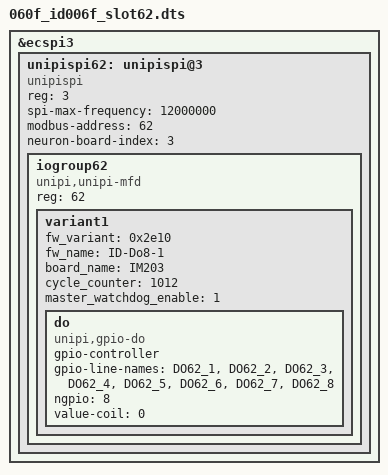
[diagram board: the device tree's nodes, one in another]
/dts-v1/;


/plugin/;

/ {
	fragment@1 {
		
		target = <&ecspi3>;
		__overlay__ {
			status = "okay";
			#address-cells = <1>;
			#size-cells = <0>;

			unipispi62: unipispi@3 {
				compatible = "unipispi";
				reg = <3>;
				status = "okay";
				spi-max-frequency = <12000000>;
				modbus-address = <62>;
				neuron-board-index = <3>;
			};
		};

	};

	fragment@2 {
		target = <&unipispi62>;
		__overlay__ {
			#address-cells = <1>;
			#size-cells = <0>;

			iogroup62 {
				reg = <62>;
				compatible = "unipi,unipi-mfd", "iogroup";
				variant1 { 
					fw_variant = <0x2e10>;
					fw_name = "ID-Do8-1";
					board_name = "IM203";
					cycle_counter = <1012>;
					master_watchdog_enable = <1>;

					do {
						compatible = "unipi,gpio-do";
						gpio-controller;
						#gpio-cells = <2>;
						gpio-line-names = "DO62_1", "DO62_2" , "DO62_3", "DO62_4", "DO62_5", "DO62_6", "DO62_7", "DO62_8";
						ngpio = <8>;
						value-coil = <0>;
					};
				};
			};
		};
	};
};
